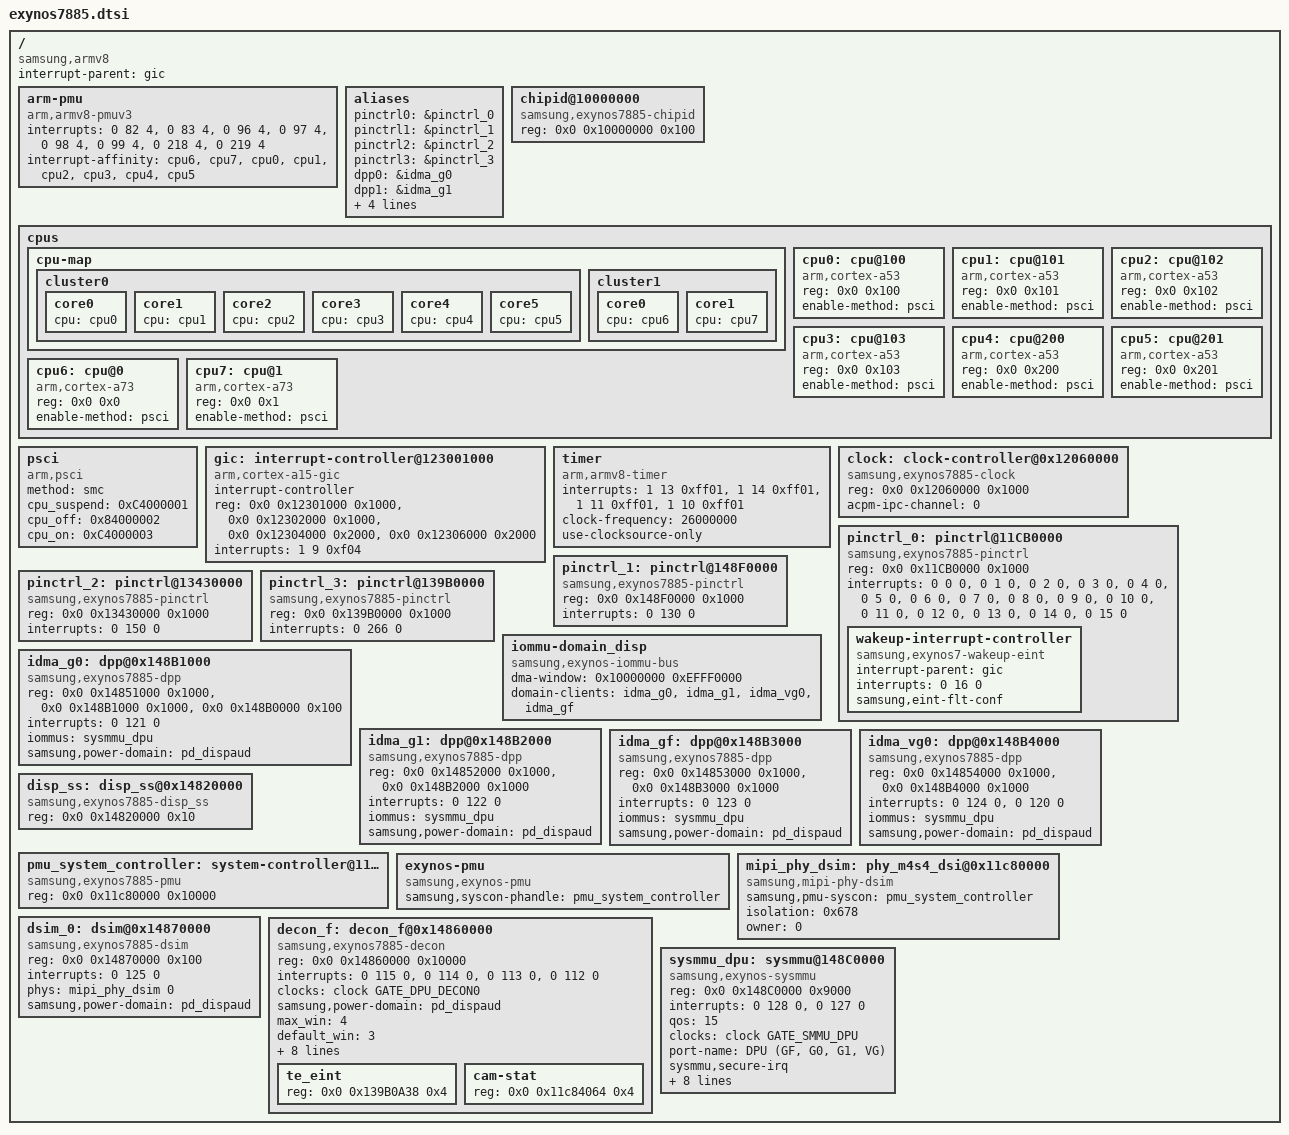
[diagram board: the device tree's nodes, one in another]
/*
 * SAMSUNG EXYNOS7885 SoC device tree source
 *
 * Copyright (c) 2014 Samsung Electronics Co., Ltd.
 *		http://www.samsung.com
 *
 * SAMSUNG EXYNOS7885 SoC device nodes are listed in this file.
 * EXYNOS7885 based board files can include this file and provide
 * values for board specfic bindings.
 *
 * This program is free software; you can redistribute it and/or modify
 * it under the terms of the GNU General Public License version 2 as
 * published by the Free Software Foundation.
 */

#include <dt-bindings/soc/samsung/exynos7885.h>
#include <dt-bindings/clock/exynos7885.h>
#include <dt-bindings/interrupt-controller/arm-gic.h>
#include <dt-bindings/sysmmu/sysmmu.h>
#include <dt-bindings/thermal/thermal.h>
#include <dt-bindings/camera/fimc_is.h>
#include "exynos7885-pinctrl.dtsi"
#include "exynos7885-pm-domains.dtsi"
#include "exynos7885-ess.dtsi"
/ {
	compatible = "samsung,armv8", "samsung,exynos7885";
	interrupt-parent = <&gic>;
	#address-cells = <2>;
	#size-cells = <1>;

	arm-pmu {
		compatible = "arm,armv8-pmuv3";
		interrupts = <0 82 4>,
			     <0 83 4>,
			     <0 96 4>,
			     <0 97 4>,
			     <0 98 4>,
			     <0 99 4>,
			     <0 218 4>,
			     <0 219 4>;
		interrupt-affinity = <&cpu6>,
					<&cpu7>,
					<&cpu0>,
					<&cpu1>,
					<&cpu2>,
					<&cpu3>,
					<&cpu4>,
					<&cpu5>;
	};

	aliases {
		pinctrl0 = &pinctrl_0;
		pinctrl1 = &pinctrl_1;
		pinctrl2 = &pinctrl_2;
		pinctrl3 = &pinctrl_3;
		dpp0 = &idma_g0;
		dpp1 = &idma_g1;
		dpp2 = &idma_vg0;
		dpp3 = &idma_gf;
		dsim0 = &dsim_0;
		decon0 = &decon_f;
	};

	chipid@10000000 {
		compatible = "samsung,exynos7885-chipid";
		reg = <0x0 0x10000000 0x100>;
	};

	cpus {
		#address-cells = <2>;
		#size-cells = <0>;

		cpu-map {
			cluster0 {
				core0 {
					cpu = <&cpu0>;
				};
				core1 {
					cpu = <&cpu1>;
				};
				core2 {
					cpu = <&cpu2>;
				};
				core3 {
					cpu = <&cpu3>;
				};
				core4 {
					cpu = <&cpu4>;
				};
				core5 {
					cpu = <&cpu5>;
				};
			};

			cluster1 {
				core0 {
					cpu = <&cpu6>;
				};
				core1 {
					cpu = <&cpu7>;
				};
			};
		};

		cpu0:cpu@100 {
			device_type = "cpu";
			compatible = "arm,cortex-a53", "arm,armv8";
			reg = <0x0 0x100>;
			enable-method = "psci";
		};

		cpu1:cpu@101 {
			device_type = "cpu";
			compatible = "arm,cortex-a53", "arm,armv8";
			reg = <0x0 0x101>;
			enable-method = "psci";
		};

		cpu2:cpu@102 {
			device_type = "cpu";
			compatible = "arm,cortex-a53", "arm,armv8";
			reg = <0x0 0x102>;
			enable-method = "psci";
		};

		cpu3:cpu@103 {
			device_type = "cpu";
			compatible = "arm,cortex-a53", "arm,armv8";
			reg = <0x0 0x103>;
			enable-method = "psci";
		};

		cpu4:cpu@200 {
			device_type = "cpu";
			compatible = "arm,cortex-a53", "arm,armv8";
			reg = <0x0 0x200>;
			enable-method = "psci";
		};

		cpu5:cpu@201 {
			device_type = "cpu";
			compatible = "arm,cortex-a53", "arm,armv8";
			reg = <0x0 0x201>;
			enable-method = "psci";
		};

		cpu6: cpu@0 {
			device_type = "cpu";
			compatible = "arm,cortex-a73", "arm,armv8";
			reg = <0x0 0x0>;
			enable-method = "psci";
		};

		cpu7:cpu@1 {
			device_type = "cpu";
			compatible = "arm,cortex-a73", "arm,armv8";
			reg = <0x0 0x1>;
			enable-method = "psci";
		};
	};

	psci {
                compatible = "arm,psci";
                method = "smc";
                cpu_suspend = <0xC4000001>;
                cpu_off = <0x84000002>;
                cpu_on = <0xC4000003>;
        };

	gic:interrupt-controller@123001000 {
		compatible = "arm,cortex-a15-gic", "arm,cortex-a9-gic";
		#interrupt-cells = <3>;
		#address-cells = <0>;
		interrupt-controller;
		reg =	<0x0 0x12301000 0x1000>,
			<0x0 0x12302000 0x1000>,
			<0x0 0x12304000 0x2000>,
			<0x0 0x12306000 0x2000>;
		interrupts = <1 9 0xf04>;
	};

	timer {
	        compatible = "arm,armv8-timer";
	        interrupts = <1 13 0xff01>,
	                     <1 14 0xff01>,
	                     <1 11 0xff01>,
	                     <1 10 0xff01>;
	        clock-frequency = <26000000>;
		use-clocksource-only;
	};

	clock: clock-controller@0x12060000 {
		compatible = "samsung,exynos7885-clock";
		reg = <0x0 0x12060000 0x1000>;
		#clock-cells = <1>;
		acpm-ipc-channel = <0>;
	};

	/* ALIVE */
	pinctrl_0: pinctrl@11CB0000 {
		compatible = "samsung,exynos7885-pinctrl";
		reg = <0x0 0x11CB0000 0x1000>;
		interrupts = <0 0 0>, <0 1 0>, <0 2 0>, <0 3 0>,
				<0 4 0>, <0 5 0>, <0 6 0>, <0 7 0>,
				<0 8 0>, <0 9 0>, <0 10 0>, <0 11 0>,
				<0 12 0>, <0 13 0>, <0 14 0>, <0 15 0>;
		wakeup-interrupt-controller {
			compatible = "samsung,exynos7-wakeup-eint";
			interrupt-parent = <&gic>;
			interrupts = <0 16 0>;
			samsung,eint-flt-conf;
		};
	};

	/* DISPAUD */
	pinctrl_1: pinctrl@148F0000 {
		compatible = "samsung,exynos7885-pinctrl";
		reg = <0x0 0x148F0000 0x1000>;
		interrupts = <0 130 0>;
	};

	/* FSYS */
	pinctrl_2: pinctrl@13430000 {
		compatible = "samsung,exynos7885-pinctrl";
		reg = <0x0 0x13430000 0x1000>;
		interrupts = <0 150 0>;
	};

	/* TOP */
	pinctrl_3: pinctrl@139B0000 {
		compatible = "samsung,exynos7885-pinctrl";
		reg = <0x0 0x139B0000 0x1000>;
		interrupts = <0 266 0>;
	};

	iommu-domain_disp {
		compatible = "samsung,exynos-iommu-bus";
		#dma-address-cells = <1>;
		#dma-size-cells = <1>;
		ranges;
		/* start address, size */
		dma-window = <0x10000000 0xEFFF0000>;

		domain-clients = <&idma_g0>, <&idma_g1>, <&idma_vg0>, <&idma_gf>;
	};

	idma_g0: dpp@0x148B1000{
		compatible = "samsung,exynos7885-dpp";
		#pb-id-cells = <3>;
		reg = <0x0 0x14851000 0x1000>, <0x0 0x148B1000 0x1000>, <0x0 0x148B0000 0x100>;
		interrupts = <0 121 0>;
		iommus = <&sysmmu_dpu>;

		/* power domain */
		samsung,power-domain = <&pd_dispaud>;
//		memory-region = <&fb_handover>;
	};

	idma_g1: dpp@0x148B2000{
		compatible = "samsung,exynos7885-dpp";
		#pb-id-cells = <3>;
		reg = <0x0 0x14852000 0x1000>, <0x0 0x148B2000 0x1000>;
		interrupts = <0 122 0>;
		iommus = <&sysmmu_dpu>;

		/* power domain */
		samsung,power-domain = <&pd_dispaud>;
	};

	idma_gf: dpp@0x148B3000{
		compatible = "samsung,exynos7885-dpp";
		#pb-id-cells = <3>;
		reg = <0x0 0x14853000 0x1000>, <0x0 0x148B3000 0x1000>;
		interrupts = <0 123 0>;
		iommus = <&sysmmu_dpu>;

		/* power domain */
		samsung,power-domain = <&pd_dispaud>;
	};

	idma_vg0: dpp@0x148B4000{
		compatible = "samsung,exynos7885-dpp";
		#pb-id-cells = <3>;
		reg = <0x0 0x14854000 0x1000>, <0x0 0x148B4000 0x1000>;
		interrupts = <0 124 0>, <0 120 0>;
		iommus = <&sysmmu_dpu>;

		/* power domain */
		samsung,power-domain = <&pd_dispaud>;
	};

	disp_ss: disp_ss@0x14820000 {
		compatible = "samsung,exynos7885-disp_ss";
		reg = <0x0 0x14820000 0x10>;
	};

	pmu_system_controller: system-controller@11c80000 {
		compatible = "samsung,exynos7885-pmu", "syscon";
		reg = <0x0 0x11c80000 0x10000>;
	};

	exynos-pmu {
		compatible = "samsung,exynos-pmu";
		samsung,syscon-phandle = <&pmu_system_controller>;
	};

	mipi_phy_dsim: phy_m4s4_dsi@0x11c80000 {
		compatible = "samsung,mipi-phy-dsim";
		samsung,pmu-syscon = <&pmu_system_controller>;
		isolation = <0x678>;
		/* PHY reset be controlled from DSIM */
		/* reg = <0x0 0x12821008 0x4>; */
		/* reset = <0 1>; */
		/* init = <4 5>; */ /* PHY reset control path bit of SYSREG */
		owner = <0>; /* 0: DSI,  1: CSI */
		#phy-cells = <1>;
	};

	dsim_0: dsim@0x14870000 {
		compatible = "samsung,exynos7885-dsim";
		reg = <0x0 0x14870000 0x100>;
		interrupts = <0 125 0>;

		phys = <&mipi_phy_dsim 0>;
		phy-names = "dsim_dphy";

		/* power domain */
		samsung,power-domain = <&pd_dispaud>;
	};

	decon_f: decon_f@0x14860000 {
		compatible = "samsung,exynos7885-decon";
		#pb-id-cells = <4>;
		reg = <0x0 0x14860000 0x10000>;

		/* under-run, frame start, frame done, extra */
		interrupts = <0 115 0>, <0 114 0>, <0 113 0>, <0 112 0>;

		/* clock */
		clock-names = "aclk";
		clocks = <&clock GATE_DPU_DECON0>;

		/* pinctrl */
//		pinctrl-names = "hw_te_on", "hw_te_off";
//		pinctrl-0 = <&decon_f_te_on>;
//		pinctrl-1 = <&decon_f_te_off>;

		/* power domain */
		samsung,power-domain = <&pd_dispaud>;

		max_win = <4>; /* chagne to 6 ->4 */
		default_win = <3>;
		default_idma = <0>;
		psr_mode = <2>;         /* 0: video mode, 1: DP command mode, 2: MIPI command mode */
		trig_mode = <0>;        /* 0: hw trigger, 1: sw trigger */
		dsi_mode = <0>;         /* 0: single dsi, 1: dual dsi */

		/* 0: DSI, 1: eDP, 2:HDMI, 3: WB */
		out_type = <0>;
		/* 0: DSI0, 1: DSI1, 2: DSI2 */
		out_idx = <0>;

		disp_freq = <0>;

		#address-cells = <2>;
		#size-cells = <1>;
		ranges;

		/* EINT for TE */
		/* TE is located in TOP */
		gpios = <&gpc0 3 0xf>;
		/* sw te pending register */
		te_eint {
			/* NWEINT_GPC0_PEND (GPC0_3:TE) */
			reg = <0x0 0x139B0A38 0x4>;
		};

		cam-stat {
			reg = <0x0 0x11c84064 0x4>;
		};
	};

	sysmmu_dpu: sysmmu@148C0000 {
		compatible = "samsung,exynos-sysmmu";
		reg = <0x0 0x148C0000 0x9000>;
		interrupts = <0 128 0>, <0 127 0>;
		qos = <15>;
		clock-names = "aclk";
		clocks = <&clock GATE_SMMU_DPU>;
		port-name = "DPU (GF, G0, G1, VG)";
		sysmmu,secure-irq;
		sysmmu,secure_base = <0x148D0000>;
		sysmmu,tlb_property =
			/* GF, G0, G1, VG */
			<(SYSMMU_PORT_PREFETCH_PREDICTION_READ(0x0)	| SYSMMU_BL1) SYSMMU_NOID>,
			<(SYSMMU_PORT_PREFETCH_PREDICTION_READ(0x1)	| SYSMMU_BL1) SYSMMU_ID_MASK(0x1, 0xFFFF)>,
			<(SYSMMU_PORT_PREFETCH_PREDICTION_READ(0x1)	| SYSMMU_BL1) SYSMMU_ID_MASK(0x0, 0xFFFF)>,
			<(SYSMMU_PORT_PREFETCH_PREDICTION_READ(0x1)	| SYSMMU_BL1) SYSMMU_ID_MASK(0x2, 0xFFFF)>,
			<(SYSMMU_PORT_PREFETCH_PREDICTION_READ(0x1)	| SYSMMU_BL1) SYSMMU_ID_MASK(0x6, 0xFFFF)>,
			<(SYSMMU_PORT_PREFETCH_PREDICTION_READ(0x1)	| SYSMMU_BL1) SYSMMU_ID_MASK(0x8, 0xFFFF)>;
		#iommu-cells = <0>;
	};
};
